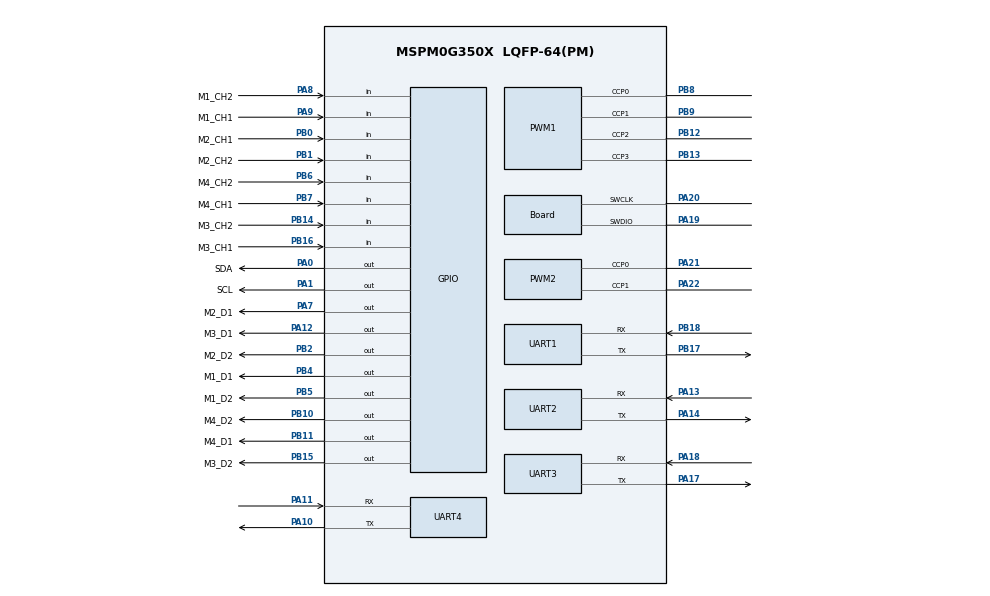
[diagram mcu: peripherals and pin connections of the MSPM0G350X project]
/**
 * These arguments were used when this file was generated. They will be automatically applied on subsequent loads
 * via the GUI or CLI. Run CLI with '--help' for additional information on how to override these arguments.
 * @cliArgs --device "MSPM0G350X" --package "LQFP-64(PM)" --part "Default" --product "mspm0_sdk@2.01.00.03"
 * @versions {"tool":"1.20.0+3587"}
 */

/**
 * Import the modules used in this configuration.
 */
const DMA           = scripting.addModule("/ti/driverlib/DMA");
const GPIO          = scripting.addModule("/ti/driverlib/GPIO", {}, false);
const GPIO1         = GPIO.addInstance();
const GPIO2         = GPIO.addInstance();
const GPIO3         = GPIO.addInstance();
const GPIO4         = GPIO.addInstance();
const GPIO5         = GPIO.addInstance();
const I2C           = scripting.addModule("/ti/driverlib/I2C", {}, false);
const I2C1          = I2C.addInstance();
const PWM           = scripting.addModule("/ti/driverlib/PWM", {}, false);
const PWM1          = PWM.addInstance();
const PWM2          = PWM.addInstance();
const SYSCTL        = scripting.addModule("/ti/driverlib/SYSCTL");
const TIMER         = scripting.addModule("/ti/driverlib/TIMER", {}, false);
const TIMER1        = TIMER.addInstance();
const UART          = scripting.addModule("/ti/driverlib/UART", {}, false);
const UART1         = UART.addInstance();
const UART2         = UART.addInstance();
const UART3         = UART.addInstance();
const UART4         = UART.addInstance();
const ProjectConfig = scripting.addModule("/ti/project_config/ProjectConfig");

/**
 * Write custom configuration values to the imported modules.
 */
const Board                       = scripting.addModule("/ti/driverlib/Board", {}, false);
Board.peripheral.$assign          = "DEBUGSS";
Board.peripheral.swclkPin.$assign = "PA20";
Board.peripheral.swdioPin.$assign = "PA19";

GPIO1.$name                               = "M1";
GPIO1.associatedPins.create(4);
GPIO1.associatedPins[0].$name             = "M1_D1";
GPIO1.associatedPins[0].pin.$assign       = "PB4";
GPIO1.associatedPins[1].$name             = "M1_D2";
GPIO1.associatedPins[1].pin.$assign       = "PB5";
GPIO1.associatedPins[2].$name             = "M1_CH1";
GPIO1.associatedPins[2].direction         = "INPUT";
GPIO1.associatedPins[2].interruptEn       = true;
GPIO1.associatedPins[2].interruptPriority = "0";
GPIO1.associatedPins[2].polarity          = "RISE";
GPIO1.associatedPins[2].pin.$assign       = "PA9";
GPIO1.associatedPins[3].$name             = "M1_CH2";
GPIO1.associatedPins[3].direction         = "INPUT";
GPIO1.associatedPins[3].pin.$assign       = "PA8";

GPIO2.$name                               = "M2";
GPIO2.associatedPins.create(4);
GPIO2.associatedPins[0].$name             = "M2_D1";
GPIO2.associatedPins[0].pin.$assign       = "PA7";
GPIO2.associatedPins[1].$name             = "M2_D2";
GPIO2.associatedPins[1].pin.$assign       = "PB2";
GPIO2.associatedPins[2].$name             = "M2_CH1";
GPIO2.associatedPins[2].direction         = "INPUT";
GPIO2.associatedPins[2].interruptEn       = true;
GPIO2.associatedPins[2].interruptPriority = "0";
GPIO2.associatedPins[2].polarity          = "RISE";
GPIO2.associatedPins[2].pin.$assign       = "PB0";
GPIO2.associatedPins[3].$name             = "M2_CH2";
GPIO2.associatedPins[3].direction         = "INPUT";
GPIO2.associatedPins[3].pin.$assign       = "PB1";

GPIO3.$name                               = "M3";
GPIO3.associatedPins.create(4);
GPIO3.associatedPins[0].$name             = "M3_D1";
GPIO3.associatedPins[0].pin.$assign       = "PA12";
GPIO3.associatedPins[1].$name             = "M3_D2";
GPIO3.associatedPins[1].pin.$assign       = "PB15";
GPIO3.associatedPins[2].$name             = "M3_CH1";
GPIO3.associatedPins[2].direction         = "INPUT";
GPIO3.associatedPins[2].interruptEn       = true;
GPIO3.associatedPins[2].interruptPriority = "0";
GPIO3.associatedPins[2].polarity          = "RISE";
GPIO3.associatedPins[2].pin.$assign       = "PB16";
GPIO3.associatedPins[3].$name             = "M3_CH2";
GPIO3.associatedPins[3].direction         = "INPUT";
GPIO3.associatedPins[3].pin.$assign       = "PB14";

GPIO4.$name                               = "M4";
GPIO4.associatedPins.create(4);
GPIO4.associatedPins[0].$name             = "M4_D1";
GPIO4.associatedPins[0].pin.$assign       = "PB11";
GPIO4.associatedPins[1].$name             = "M4_D2";
GPIO4.associatedPins[1].pin.$assign       = "PB10";
GPIO4.associatedPins[2].$name             = "M4_CH1";
GPIO4.associatedPins[2].direction         = "INPUT";
GPIO4.associatedPins[2].interruptEn       = true;
GPIO4.associatedPins[2].interruptPriority = "0";
GPIO4.associatedPins[2].polarity          = "RISE";
GPIO4.associatedPins[2].pin.$assign       = "PB7";
GPIO4.associatedPins[3].$name             = "M4_CH2";
GPIO4.associatedPins[3].direction         = "INPUT";
GPIO4.associatedPins[3].pin.$assign       = "PB6";

GPIO5.$name                         = "IIC_GYR";
GPIO5.associatedPins.create(2);
GPIO5.associatedPins[0].$name       = "SDA";
GPIO5.associatedPins[0].ioStructure = "OD";
GPIO5.associatedPins[0].pin.$assign = "PA0";
GPIO5.associatedPins[1].$name       = "SCL";
GPIO5.associatedPins[1].ioStructure = "OD";
GPIO5.associatedPins[1].pin.$assign = "PA1";

I2C1.$name                             = "I2C_1";
I2C1.peripheral.$assign                = "I2C1";
I2C1.sdaPinConfig.hideOutputInversion  = scripting.forceWrite(false);
I2C1.sdaPinConfig.onlyInternalResistor = scripting.forceWrite(false);
I2C1.sdaPinConfig.passedPeripheralType = scripting.forceWrite("Digital");
I2C1.sdaPinConfig.$name                = "ti_driverlib_gpio_GPIOPinGeneric8";
I2C1.sclPinConfig.hideOutputInversion  = scripting.forceWrite(false);
I2C1.sclPinConfig.onlyInternalResistor = scripting.forceWrite(false);
I2C1.sclPinConfig.passedPeripheralType = scripting.forceWrite("Digital");
I2C1.sclPinConfig.$name                = "ti_driverlib_gpio_GPIOPinGeneric9";

PWM1.$name                              = "M_PWM";
PWM1.ccIndex                            = [0,1,2,3];
PWM1.timerCount                         = 10000;
PWM1.timerStartTimer                    = true;
PWM1.pwmMode                            = "EDGE_ALIGN_UP";
PWM1.peripheral.$assign                 = "TIMA0";
PWM1.peripheral.ccp0Pin.$assign         = "PB8";
PWM1.peripheral.ccp1Pin.$assign         = "PB9";
PWM1.peripheral.ccp2Pin.$assign         = "PB12";
PWM1.peripheral.ccp3Pin.$assign         = "PB13";
PWM1.PWM_CHANNEL_0.$name                = "ti_driverlib_pwm_PWMTimerCC0";
PWM1.PWM_CHANNEL_1.$name                = "ti_driverlib_pwm_PWMTimerCC1";
PWM1.ccp0PinConfig.direction            = scripting.forceWrite("OUTPUT");
PWM1.ccp0PinConfig.hideOutputInversion  = scripting.forceWrite(false);
PWM1.ccp0PinConfig.onlyInternalResistor = scripting.forceWrite(false);
PWM1.ccp0PinConfig.passedPeripheralType = scripting.forceWrite("Digital");
PWM1.ccp0PinConfig.$name                = "ti_driverlib_gpio_GPIOPinGeneric10";
PWM1.ccp1PinConfig.direction            = scripting.forceWrite("OUTPUT");
PWM1.ccp1PinConfig.hideOutputInversion  = scripting.forceWrite(false);
PWM1.ccp1PinConfig.onlyInternalResistor = scripting.forceWrite(false);
PWM1.ccp1PinConfig.passedPeripheralType = scripting.forceWrite("Digital");
PWM1.ccp1PinConfig.$name                = "ti_driverlib_gpio_GPIOPinGeneric11";
PWM1.PWM_CHANNEL_2.$name                = "ti_driverlib_pwm_PWMTimerCC2";
PWM1.PWM_CHANNEL_3.$name                = "ti_driverlib_pwm_PWMTimerCC3";
PWM1.ccp2PinConfig.$name                = "ti_driverlib_gpio_GPIOPinGeneric12";
PWM1.ccp3PinConfig.$name                = "ti_driverlib_gpio_GPIOPinGeneric13";

PWM2.$name                              = "SERVO";
PWM2.clockDivider                       = 8;
PWM2.clockPrescale                      = 25;
PWM2.timerCount                         = 3200;
PWM2.pwmMode                            = "EDGE_ALIGN_UP";
PWM2.timerStartTimer                    = true;
PWM2.peripheral.ccp0Pin.$assign         = "PA21";
PWM2.peripheral.ccp1Pin.$assign         = "PA22";
PWM2.PWM_CHANNEL_0.$name                = "ti_driverlib_pwm_PWMTimerCC4";
PWM2.PWM_CHANNEL_1.$name                = "ti_driverlib_pwm_PWMTimerCC5";
PWM2.ccp0PinConfig.direction            = scripting.forceWrite("OUTPUT");
PWM2.ccp0PinConfig.hideOutputInversion  = scripting.forceWrite(false);
PWM2.ccp0PinConfig.onlyInternalResistor = scripting.forceWrite(false);
PWM2.ccp0PinConfig.passedPeripheralType = scripting.forceWrite("Digital");
PWM2.ccp0PinConfig.$name                = "ti_driverlib_gpio_GPIOPinGeneric16";
PWM2.ccp1PinConfig.direction            = scripting.forceWrite("OUTPUT");
PWM2.ccp1PinConfig.hideOutputInversion  = scripting.forceWrite(false);
PWM2.ccp1PinConfig.onlyInternalResistor = scripting.forceWrite(false);
PWM2.ccp1PinConfig.passedPeripheralType = scripting.forceWrite("Digital");
PWM2.ccp1PinConfig.$name                = "ti_driverlib_gpio_GPIOPinGeneric17";

SYSCTL.forceDefaultClkConfig = true;
SYSCTL.peripheral.$assign    = "SYSCTL";

TIMER1.$name              = "TIMER_INT";
TIMER1.timerClkPrescale   = 256;
TIMER1.timerMode          = "PERIODIC";
TIMER1.interrupts         = ["ZERO"];
TIMER1.interruptPriority  = "1";
TIMER1.timerPeriod        = "50ms";
TIMER1.peripheral.$assign = "TIMG0";

UART1.$name                            = "UART_2";
UART1.enabledDMATXTriggers             = "DL_UART_DMA_INTERRUPT_TX";
UART1.peripheral.rxPin.$assign         = "PB18";
UART1.peripheral.txPin.$assign         = "PB17";
UART1.txPinConfig.direction            = scripting.forceWrite("OUTPUT");
UART1.txPinConfig.hideOutputInversion  = scripting.forceWrite(false);
UART1.txPinConfig.onlyInternalResistor = scripting.forceWrite(false);
UART1.txPinConfig.passedPeripheralType = scripting.forceWrite("Digital");
UART1.txPinConfig.$name                = "ti_driverlib_gpio_GPIOPinGeneric0";
UART1.rxPinConfig.hideOutputInversion  = scripting.forceWrite(false);
UART1.rxPinConfig.onlyInternalResistor = scripting.forceWrite(false);
UART1.rxPinConfig.passedPeripheralType = scripting.forceWrite("Digital");
UART1.rxPinConfig.$name                = "ti_driverlib_gpio_GPIOPinGeneric1";
UART1.DMA_CHANNEL_TX.addressMode       = "b2f";
UART1.DMA_CHANNEL_TX.srcLength         = "BYTE";
UART1.DMA_CHANNEL_TX.dstLength         = "BYTE";
UART1.DMA_CHANNEL_TX.$name             = "DMA_CH2";

UART2.$name                      = "UART_1";
UART2.enabledDMATXTriggers       = "DL_UART_DMA_INTERRUPT_TX";
UART2.targetBaudRate             = 115200;
UART2.peripheral.$assign         = "UART3";
UART2.peripheral.rxPin.$assign   = "PA13";
UART2.peripheral.txPin.$assign   = "PA14";
UART2.txPinConfig.$name          = "ti_driverlib_gpio_GPIOPinGeneric2";
UART2.rxPinConfig.$name          = "ti_driverlib_gpio_GPIOPinGeneric3";
UART2.DMA_CHANNEL_TX.addressMode = "b2f";
UART2.DMA_CHANNEL_TX.srcLength   = "BYTE";
UART2.DMA_CHANNEL_TX.dstLength   = "BYTE";
UART2.DMA_CHANNEL_TX.$name       = "DMA_CH1";

UART3.$name                            = "UART_4";
UART3.enabledDMATXTriggers             = "DL_UART_DMA_INTERRUPT_TX";
UART3.peripheral.rxPin.$assign         = "PA18";
UART3.peripheral.txPin.$assign         = "PA17";
UART3.txPinConfig.direction            = scripting.forceWrite("OUTPUT");
UART3.txPinConfig.hideOutputInversion  = scripting.forceWrite(false);
UART3.txPinConfig.onlyInternalResistor = scripting.forceWrite(false);
UART3.txPinConfig.passedPeripheralType = scripting.forceWrite("Digital");
UART3.txPinConfig.$name                = "ti_driverlib_gpio_GPIOPinGeneric4";
UART3.rxPinConfig.hideOutputInversion  = scripting.forceWrite(false);
UART3.rxPinConfig.onlyInternalResistor = scripting.forceWrite(false);
UART3.rxPinConfig.passedPeripheralType = scripting.forceWrite("Digital");
UART3.rxPinConfig.$name                = "ti_driverlib_gpio_GPIOPinGeneric5";
UART3.DMA_CHANNEL_TX.addressMode       = "b2f";
UART3.DMA_CHANNEL_TX.srcLength         = "BYTE";
UART3.DMA_CHANNEL_TX.dstLength         = "BYTE";
UART3.DMA_CHANNEL_TX.$name             = "DMA_CH4";

UART4.$name                      = "UART_3";
UART4.enabledDMATXTriggers       = "DL_UART_DMA_INTERRUPT_TX";
UART4.peripheral.rxPin.$assign   = "PA11";
UART4.peripheral.txPin.$assign   = "PA10";
UART4.txPinConfig.$name          = "ti_driverlib_gpio_GPIOPinGeneric6";
UART4.rxPinConfig.$name          = "ti_driverlib_gpio_GPIOPinGeneric7";
UART4.DMA_CHANNEL_TX.$name       = "DMA_CH3";
UART4.DMA_CHANNEL_TX.addressMode = "b2f";
UART4.DMA_CHANNEL_TX.srcLength   = "BYTE";
UART4.DMA_CHANNEL_TX.dstLength   = "BYTE";

ProjectConfig.deviceSpin = "MSPM0G3507";

/**
 * Pinmux solution for unlocked pins/peripherals. This ensures that minor changes to the automatic solver in a future
 * version of the tool will not impact the pinmux you originally saw.  These lines can be completely deleted in order to
 * re-solve from scratch.
 */
I2C1.peripheral.sdaPin.$suggestSolution          = "PA16";
I2C1.peripheral.sclPin.$suggestSolution          = "PA15";
PWM2.peripheral.$suggestSolution                 = "TIMG6";
UART1.peripheral.$suggestSolution                = "UART2";
UART1.DMA_CHANNEL_TX.peripheral.$suggestSolution = "DMA_CH3";
UART2.DMA_CHANNEL_TX.peripheral.$suggestSolution = "DMA_CH2";
UART3.peripheral.$suggestSolution                = "UART1";
UART3.DMA_CHANNEL_TX.peripheral.$suggestSolution = "DMA_CH1";
UART4.peripheral.$suggestSolution                = "UART0";
UART4.DMA_CHANNEL_TX.peripheral.$suggestSolution = "DMA_CH0";
